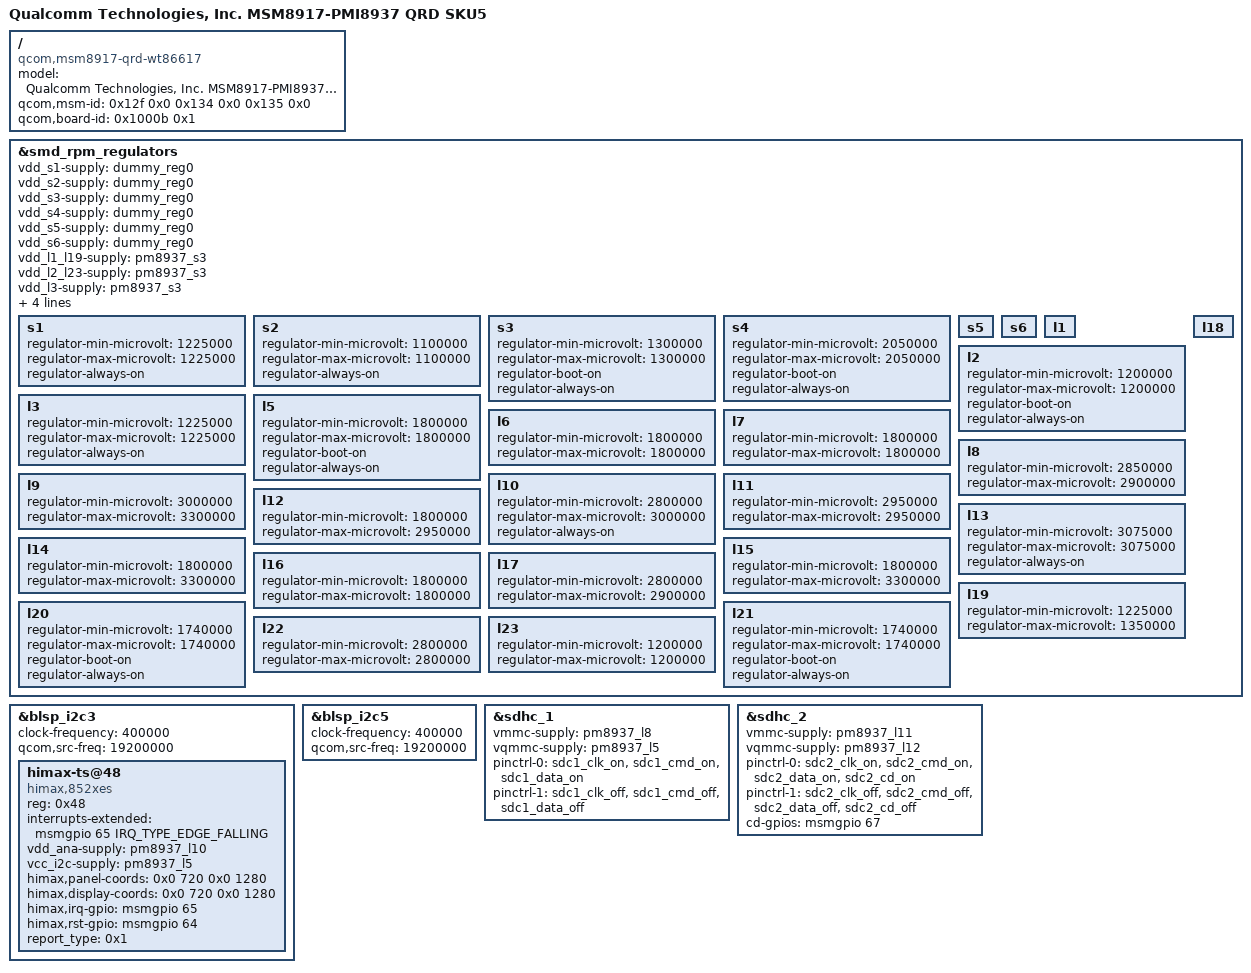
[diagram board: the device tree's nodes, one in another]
// SPDX-License-Identifier: GPL-2.0

/dts-v1/;

#include "msm8917.dtsi"

/ {
	model = "Qualcomm Technologies, Inc. MSM8917-PMI8937 QRD SKU5";
	compatible = "qcom,msm8917-qrd-wt86617", "qcom,msm8917-qrd", "qcom,msm8917", "qcom,qrd";
	qcom,msm-id = <0x12f 0x0 0x134 0x0 0x135 0x0>;
	qcom,board-id = <0x1000b 0x1>;
};

&smd_rpm_regulators {
	vdd_s1-supply = <&dummy_reg0>;
	vdd_s2-supply = <&dummy_reg0>;
	vdd_s3-supply = <&dummy_reg0>;
	vdd_s4-supply = <&dummy_reg0>;
	vdd_s5-supply = <&dummy_reg0>;
	vdd_s6-supply = <&dummy_reg0>;
	vdd_l1_l19-supply = <&pm8937_s3>;
	vdd_l2_l23-supply = <&pm8937_s3>;
	vdd_l3-supply = <&pm8937_s3>;
	vdd_l4_l5_l6_l7_l16-supply = <&pm8937_s4>;
	vdd_l20_l21-supply = <&pm8937_s4>;
	vdd_l8_l11_l12_l17_l22-supply = <&dummy_reg0>;
	vdd_l9_l10_l13_l14_l15_l18-supply = <&dummy_reg0>;

	/* MSM modem */
	s1 {
		//regulator-min-microvolt = <1000000>;
		regulator-min-microvolt = <1225000>;
		regulator-max-microvolt = <1225000>;
		regulator-always-on; // XXX
	};

	/* MSM core and graphics */
	s2 {
		regulator-min-microvolt = <1100000>;
		regulator-max-microvolt = <1100000>;
		regulator-always-on; // XXX
	};

	s3 {
		regulator-min-microvolt = <1300000>;
		regulator-max-microvolt = <1300000>;
		regulator-boot-on;
		regulator-always-on;
	};

	s4 {
		regulator-min-microvolt = <2050000>;
		regulator-max-microvolt = <2050000>;
		regulator-boot-on;
		regulator-always-on;
	};

	/* MSM applications processor */
	s5 {
	};

	/* MSM applications processor */
	s6 {
	};

	/* RFICs */
	l1 {
	};

	/* LPDDR2/LPDDR3, MIPI CSI, and DSI */
	l2 {
		regulator-min-microvolt = <1200000>;
		regulator-max-microvolt = <1200000>;
		regulator-boot-on;
		regulator-always-on;
	};

	/* VDDMX */
	l3 {
		regulator-min-microvolt = <1225000>;
		regulator-max-microvolt = <1225000>;
		regulator-always-on; // XXX
	};

	/* Most digital I/Os, MSM pad groups 3 and 7, LPDDR, and eMMC */
	l5 {
		regulator-min-microvolt = <1800000>;
		regulator-max-microvolt = <1800000>;
		regulator-boot-on;
		regulator-always-on;
	};

	/* MSM DSI PLL and OTP, camera, touchscreen, display, and sensors */
	l6 {
		regulator-min-microvolt = <1800000>;
		regulator-max-microvolt = <1800000>;
	};

	/* MSM analog and PLLs, WCN XO, and PM baseband clock driver */
	l7 {
		regulator-min-microvolt = <1800000>;
		regulator-max-microvolt = <1800000>;
	};

	/* eMMC */
	l8 {
		regulator-min-microvolt = <2850000>;
		regulator-max-microvolt = <2900000>;
	};

	/* WCN */
	l9 {
		regulator-min-microvolt = <3000000>;
		regulator-max-microvolt = <3300000>;
	};

	/* Sensors */
	l10 {
		regulator-min-microvolt = <2800000>;
		regulator-max-microvolt = <3000000>;
		regulator-always-on; // XXX touch
	};

	/* Micro SD */
	l11 {
		regulator-min-microvolt = <2950000>;
		regulator-max-microvolt = <2950000>;
	};

	/* MSM pad group 2 and SDC2 */
	l12 {
		regulator-min-microvolt = <1800000>;
		regulator-max-microvolt = <2950000>;
	};

	/* MSM USB and audio */
	l13 {
		regulator-min-microvolt = <3075000>;
		regulator-max-microvolt = <3075000>;
		regulator-always-on; // XXX audio (micbias+)
	};

	/* MSM pad group 5, dual-voltage UIM1, and NFC */
	l14 {
		regulator-min-microvolt = <1800000>;
		regulator-max-microvolt = <3300000>;
	};

	/* MSM pad group 6 and dual-voltage UIM2 */
	l15 {
		regulator-min-microvolt = <1800000>;
		regulator-max-microvolt = <3300000>;
	};

	/* PMIC HKADC */
	l16 {
		regulator-min-microvolt = <1800000>;
		regulator-max-microvolt = <1800000>;
	};

	/* Camera, display, and touchscreen */
	l17 {
		regulator-min-microvolt = <2800000>;
		regulator-max-microvolt = <2900000>;
	};

	/* QTI RF front-end */
	l18 {
	};

	/* MSM analog, WCN, and WGR */
	l19 {
		regulator-min-microvolt = <1225000>;
		regulator-max-microvolt = <1350000>;
	};

	/* PMIC XO circuits */
	l20 {
		regulator-min-microvolt = <1740000>;
		regulator-max-microvolt = <1740000>;
		regulator-boot-on;
		regulator-always-on;
	};

	/* PMIC RF clock buffers */
	l21 {
		regulator-min-microvolt = <1740000>;
		regulator-max-microvolt = <1740000>;
		regulator-boot-on;
		regulator-always-on;
	};

	/* Camera - analog */
	l22 {
		regulator-min-microvolt = <2800000>;
		regulator-max-microvolt = <2800000>;
	};

	/* Camera - digital */
	l23 {
		regulator-min-microvolt = <1200000>;
		regulator-max-microvolt = <1200000>;
	};
};

&blsp_i2c3 {
	status = "okay";

	clock-frequency = <400000>;
	qcom,src-freq = <19200000>;

	himax-ts@48 {
		compatible = "himax,852xes";
		reg = <0x48>;
		interrupts-extended = <&msmgpio 65 IRQ_TYPE_EDGE_FALLING>;
		vdd_ana-supply = <&pm8937_l10>;
		vcc_i2c-supply = <&pm8937_l5>;
		himax,panel-coords = <0x0 720 0x0 1280>;
		himax,display-coords = <0x0 720 0x0 1280>;
		himax,irq-gpio = <&msmgpio 65 0x0>;
		himax,rst-gpio = <&msmgpio 64 0x0>;
		report_type = <0x1>;
		// virtualkey = <0xdc>;
	};

	/* i2cdetect shows a device at 0x4a */
};

&blsp_i2c5 {
	status = "okay";

	clock-frequency = <400000>;
	qcom,src-freq = <19200000>;

	/* i2cdetect shows a device at 0x3e */
};

&sdhc_1 {
	status = "okay";

	vmmc-supply = <&pm8937_l8>;
	vqmmc-supply = <&pm8937_l5>;

	pinctrl-names = "default", "sleep";
	pinctrl-0 = <&sdc1_clk_on &sdc1_cmd_on &sdc1_data_on>;
	pinctrl-1 = <&sdc1_clk_off &sdc1_cmd_off &sdc1_data_off>;
};

&sdhc_2 {
	status = "okay";

	vmmc-supply = <&pm8937_l11>;
	vqmmc-supply = <&pm8937_l12>;

	pinctrl-names = "default", "sleep";
	pinctrl-0 = <&sdc2_clk_on &sdc2_cmd_on &sdc2_data_on &sdc2_cd_on>;
	pinctrl-1 = <&sdc2_clk_off &sdc2_cmd_off &sdc2_data_off &sdc2_cd_off>;

	cd-gpios = <&msmgpio 67 0>;
};
